# apollo510 register map
Vendor: Ambiq Micro; Series: Apollo; File version: 1.0
CPU: CM55 r1p1, little endian, MPU, FPU, double-precision FPU, DSP, I-cache, D-cache, VTOR, ITCM, DTCM, 4 interrupt priority bits, 0 interrupts, 8 SAU regions
Registers are 32-bit, read-write, reset 0x0 unless marked. A register's access mark holds for its fields unless they carry their own. Offsets are from the block's base; [hi:lo] are bit positions; {n}, {i} and the like mark numbered series; 'fields as' and 'values as' point back to an identical list.

## STIMER — Counter/Timer
Base 0x40008800
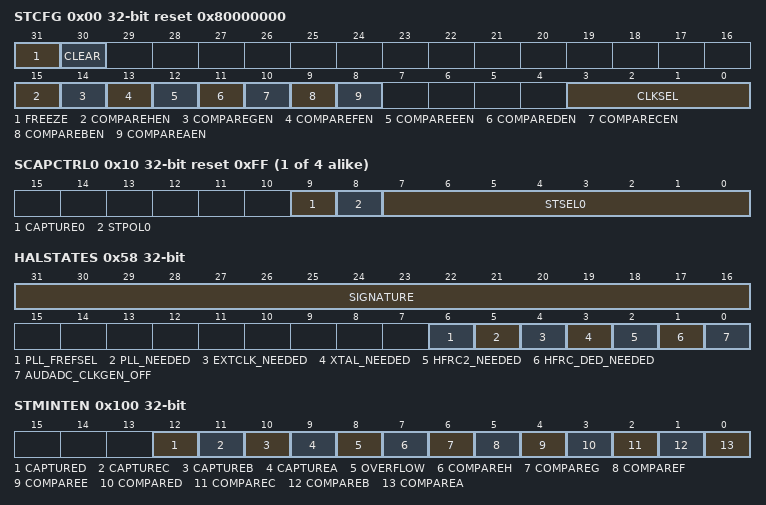
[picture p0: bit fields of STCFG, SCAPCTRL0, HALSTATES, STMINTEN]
0x00 STCFG reset 0x80000000 — The STIMER Configuration Register contains the software control for selecting the clock divider and source feeding the system timer.
  [31] FREEZE — Set this bit to one to freeze the clock input to the COUNTER register. Once frozen, the value can be safely written from the MCU. Unfreeze to resume.
    0=THAW (Let the COUNTER register run on its input clock.); 1=FREEZE (Stop the COUNTER register for loading.)
  [30] CLEAR — Set this bit to one to clear the System Timer register. If this bit is set to '1', the system timer register will stay cleared. It needs to be set to '0' for the system timer to start running.
    0=RUN (Let the COUNTER register run on its input clock.); 1=CLEAR (Stop the COUNTER register for loading.)
  [15] COMPAREHEN — Selects whether compare is enabled for the corresponding SCMPR register. If compare is enabled, the interrupt status is set once the comparision is met.
    0=DISABLE (Compare H disabled.); 1=ENABLE (Compare H enabled.)
  [14] COMPAREGEN — Selects whether compare is enabled for the corresponding SCMPR register. If compare is enabled, the interrupt status is set once the comparision is met.
    0=DISABLE (Compare G disabled.); 1=ENABLE (Compare G enabled.)
  [13] COMPAREFEN — Selects whether compare is enabled for the corresponding SCMPR register. If compare is enabled, the interrupt status is set once the comparision is met.
    0=DISABLE (Compare F disabled.); 1=ENABLE (Compare F enabled.)
  [12] COMPAREEEN — Selects whether compare is enabled for the corresponding SCMPR register. If compare is enabled, the interrupt status is set once the comparision is met.
    0=DISABLE (Compare E disabled.); 1=ENABLE (Compare E enabled.)
  [11] COMPAREDEN — Selects whether compare is enabled for the corresponding SCMPR register. If compare is enabled, the interrupt status is set once the comparision is met.
    0=DISABLE (Compare D disabled.); 1=ENABLE (Compare D enabled.)
  [10] COMPARECEN — Selects whether compare is enabled for the corresponding SCMPR register. If compare is enabled, the interrupt status is set once the comparision is met.
    0=DISABLE (Compare C disabled.); 1=ENABLE (Compare C enabled.)
  [9] COMPAREBEN — Selects whether compare is enabled for the corresponding SCMPR register. If compare is enabled, the interrupt status is set once the comparision is met.
    0=DISABLE (Compare B disabled.); 1=ENABLE (Compare B enabled.)
  [8] COMPAREAEN — Selects whether compare is enabled for the corresponding SCMPR register. If compare is enabled, the interrupt status is set once the comparision is met.
    0=DISABLE (Compare A disabled.); 1=ENABLE (Compare A enabled.)
  [3:0] CLKSEL — Selects an appropriate clock source and divider to use for the System Timer clock.
    0=NOCLK (No clock enabled.); 1=HFRC_6MHZ (6MHz from the HFRC clock divider.); 2=HFRC_375KHZ (375KHz from the HFRC clock divider.); 3=XTAL_32KHZ (32768Hz from the crystal oscillator.); 4=XTAL_16KHZ (16384Hz from the crystal oscillator.); 5=XTAL_1KHZ (1024Hz from the crystal oscillator.); 6=LFRC_NOMINAL (Approximately 900Hz from the LFRC oscillator (uncalibrated).); 7=CTIMER0 (Use CTIMER 0 for the clock source (allows prescaling from other system clocks).); 8=CTIMER1 (Use CTIMER 1 for the clock source (allows prescaling from other system clocks).)
0x04 STTMR — The COUNTER Register contains the running count of time as maintained by incrementing for every rising clock edge of the clock source selected in the configuration register. It is this counter value that captured in the capture registers and it is this counter value that is compared against the various compare registers. This register cannot be written, but can be cleared to 0 for a deterministic value. Use the FREEZE bit will stop this counter from incrementing.
  [31:0] STTMR — Value of the 32-bit counter as it ticks over.
{0x10+4i} SCAPCTRL{i} reset 0xFF (i=0..3) — The STIMER Capture Control Register controls each of the 4 capture registers. It selects their GPIO pin number for a trigger source, enables a capture operation and sets the input polarity for the capture. NOTE: 8-bit writes can control individual capture registers atomically.
  [9] CAPTURE{i} — Selects whether capture {i} is enabled for the specified capture register.
    0=DISABLE (Capture function disabled.); 1=ENABLE (Capture function enabled.)
  [8] STPOL{i} — STIMER Capture {i} Polarity.
    0=CAPLH (Capture on low to high GPIO transition); 1=CAPHL (Capture on high to low GPIO transition)
  [7:0] STSEL{i} — STIMER Capture {i} Select.
{0x20+4i} SCMPR{i} (i=0..7) — The VALUE in this bit field is used to compare against the VALUE in the COUNTER register. If the match criterion in the configuration register is met then a corresponding interrupt status bit is set. The match criterion is defined as COUNTER equal to COMPARE. To establish a desired value in this COMPARE register, write the number of ticks in the future to this register to indicate when to interrupt. The hardware does the addition to the COUNTER value in the STIMER clock domain so that the math is precise. Reading this register shows the COUNTER value at which this interrupt will occur.
  [31:0] SCMPR{i} — Compare this value to the value in the COUNTER register according to the match criterion, as selected in the COMPARE_A_EN bit in the REG_CTIMER_STCFG register.
{0x40+4i} SCAPT{i} (i=0..3) — The STIMER capture Register {i} captures the VALUE in the COUNTER register whenever capture condition (event) occurs. This register holds a time stamp for the event.
  [31:0] SCAPT{i} — Whenever the event is detected, the value in the COUNTER is copied into this register and the corresponding interrupt status bit is set.
0x50 SNVR0 — The SNVR0 Register contains a portion of the stored epoch offset associated with the time in the COUNTER register. This register is only reset by POI not by HRESETn. Its contents will survive all reset levels except POI and full power cycles.
  [31:0] SNVR0 — Value of the 32-bit counter as it ticks over.
0x54 SNVR1 — The SNVR1 Register contains a portion of the stored epoch offset associated with the time in the COUNTER register. This register is only reset by POI not by HRESETn. Its contents will survive all reset levels except POI and full power cycles.
  [31:0] SNVR1 — Value of the 32-bit counter as it ticks over.
0x58 HALSTATES — This register is reserved for internal HAL usage and is not available to the user.
  [31:16] SIGNATURE — Signature for this information.
  [6] PLL_FREFSEL — REFCLK selection for PLL.
  [5] PLL_NEEDED — PLL clock needed for mux reset.
  [4] EXTCLK_NEEDED — EXTREF clock needed for mux reset.
  [3] XTAL_NEEDED — XTAL clock needed for mux reset.
  [2] HFRC2_NEEDED — HFRC2 clock needed for mux reset.
  [1] HFRC_DED_NEEDED — HFRC_DED clock needed for mux reset.
  [0] AUDADC_CLKGEN_OFF — AUDADC ClockGen mux was at OFF position.
0x100 STMINTEN — Set bits in this register to allow this module to generate the corresponding interrupt.
  [12] CAPTURED — CAPTURE register D has grabbed the value in the counter
    1=CAPD_INT (Capture D interrupt status bit was set.); 0=CAPD_DEFAULT (Capture D interrupt status default/not set.)
  [11] CAPTUREC — CAPTURE register C has grabbed the value in the counter
    1=CAPC_INT (CAPTURE C interrupt status bit was set.); 0=CAPC_DEFAULT (CAPTURE C interrupt status default/not set.)
  [10] CAPTUREB — CAPTURE register B has grabbed the value in the counter
    1=CAPB_INT (CAPTURE B interrupt status bit was set.); 0=CAPB_DEFAULT (CAPTURE B interrupt status default/not set.)
  [9] CAPTUREA — CAPTURE register A has grabbed the value in the counter
    1=CAPA_INT (CAPTURE A interrupt status bit was set.); 0=CAPA_DEFAULT (CAPTURE A interrupt status default/not set.)
  [8] OVERFLOW — COUNTER over flowed from 0xFFFFFFFF back to 0x00000000.
    1=OFLOW_INT (Overflow interrupt status bit was set.); 0=OFLOW_DEFAULT (Overflow interrupt status bit default/not set.)
  [7] COMPAREH — COUNTER is greater than or equal to COMPARE register H.
    1=COMPARED (COUNTER greater than or equal to COMPARE register.); 0=DEFAULT (COUNTER less than COMPARE register.)
  [6] COMPAREG — COUNTER is greater than or equal to COMPARE register G.
    values as COMPAREH
  [5] COMPAREF — COUNTER is greater than or equal to COMPARE register F.
    values as COMPAREH
  [4] COMPAREE — COUNTER is greater than or equal to COMPARE register E.
    values as COMPAREH
  [3] COMPARED — COUNTER is greater than or equal to COMPARE register D.
    values as COMPAREH
  [2] COMPAREC — COUNTER is greater than or equal to COMPARE register C.
    values as COMPAREH
  [1] COMPAREB — COUNTER is greater than or equal to COMPARE register B.
    values as COMPAREH
  [0] COMPAREA — COUNTER is greater than or equal to COMPARE register A.
    values as COMPAREH
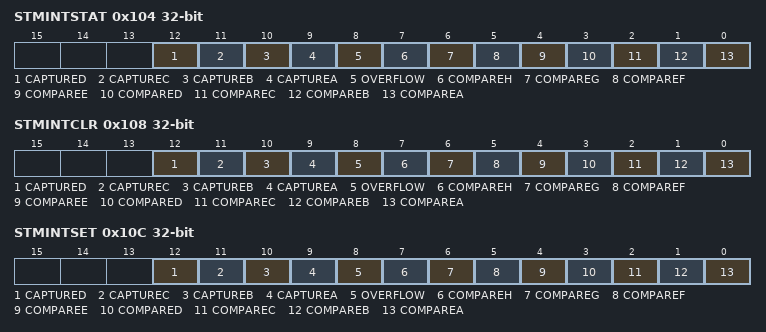
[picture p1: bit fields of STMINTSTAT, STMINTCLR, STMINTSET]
0x104 STMINTSTAT — Read bits from this register to discover the cause of a recent interrupt.
  fields as STMINTEN
0x108 STMINTCLR — Write a 1 to a bit in this register to clear the interrupt status associated with that bit.
  fields as STMINTEN
0x10C STMINTSET — Write a 1 to a bit in this register to instantly generate an interrupt from this module. (Generally used for testing purposes).
  fields as STMINTEN
